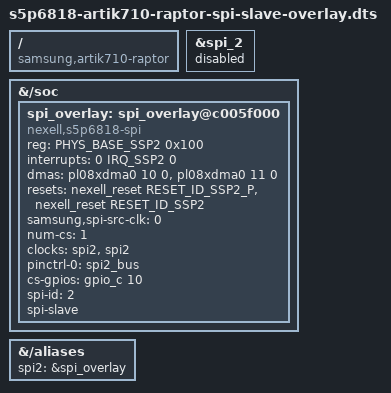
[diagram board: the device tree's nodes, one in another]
/* Enables spidev interface
 * It creates /dev/spidev2.0 node for spi slave.
 */

/dts-v1/;
/plugin/;

#include <dt-bindings/interrupt-controller/irq.h>
#include <dt-bindings/input/input.h>
#include <dt-bindings/pinctrl/nexell.h>
#include <dt-bindings/reset/nexell,s5p6818-reset.h>
#include <dt-bindings/soc/s5p6818-base.h>
#include <dt-bindings/tieoff/s5p6818-tieoff.h>
#include <dt-bindings/interrupt-controller/s5p6818-irq.h>

/ {
	compatible = "samsung,artik710-raptor";

	fragment@0 {
		target = <&spi_2>;
		__overlay__ {
			status = "disabled";

		};
	};

	fragment@1 {
		target-path = "/soc";
		__overlay__ {
			#address-cells = <1>;
			#size-cells = <1>;
			spi_overlay: spi_overlay@c005f000 {
				compatible = "nexell,s5p6818-spi";
				reg = <PHYS_BASE_SSP2 0x100>;
				interrupts = <0 IRQ_SSP2 0>;
				dmas = <&pl08xdma0 10 0>, <&pl08xdma0 11 0>;
				dma-names = "tx", "rx";
				resets = <&nexell_reset RESET_ID_SSP2_P>,
					<&nexell_reset RESET_ID_SSP2>;
				reset-names = "pre-reset","spi-reset";
				#address-cells = <1>;
				#size-cells = <0>;
				samsung,spi-src-clk = <0>;
				num-cs = <1>;
				clocks = <&spi2>, <&spi2>;
				clock-names = "spi", "spi_busclk0";
				pinctrl-names = "default";
				pinctrl-0 = <&spi2_bus>;
				cs-gpios = <&gpio_c 10 0>;
				spi-id = <2>;
				spi-slave;
				status = "okay";
			};
		};
	};

	fragment@2 {
		target-path = "/aliases";
		__overlay__ {
			spi2	= &spi_overlay;
		};
	};
};
